AUTOSAR XML (schema 4-2-1)
package /ComponentTypes
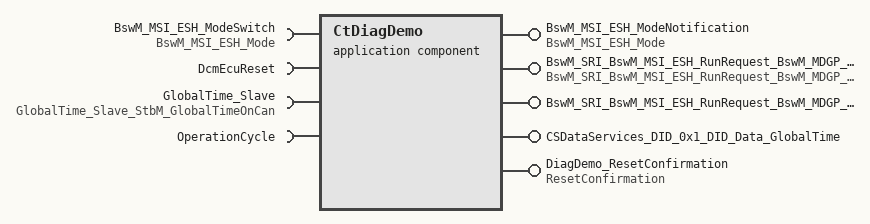
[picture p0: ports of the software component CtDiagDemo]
  application sw component type CtDiagDemo
    5 x provide port:
      BswM_MSI_ESH_ModeNotification: mode-switch-sender-com-spec{enhanced-mode-api=false, mode-group=BswM_MDGP_ESH_Mode, queue-length=1}, provided-interface=BswM_MSI_ESH_Mode
      BswM_SRI_BswM_MSI_ESH_RunRequest_BswM_MDGP_ESH_PostRunRequest: nonqueued-sender-com-spec{data-element=requestedMode, init-value=RELEASED}, provided-interface=BswM_SRI_BswM_MSI_ESH_RunRequest_BswM_MDGP_ESH_RunRequest
      BswM_SRI_BswM_MSI_ESH_RunRequest_BswM_MDGP_ESH_RunRequest: nonqueued-sender-com-spec{data-element=requestedMode, init-value=RELEASED}, provided-interface=BswM_SRI_BswM_MSI_ESH_RunRequest_BswM_MDGP_ESH_RunRequest
      CSDataServices_DID_0x1_DID_Data_GlobalTime: server-com-spec{operation=ReadData, queue-length=1}, provided-interface=CSDataServices_DID_0x1_DID_Data_GlobalTime
      DiagDemo_ResetConfirmation: server-com-spec{operation=ConfirmReset, queue-length=1}, provided-interface=ResetConfirmation
    4 x require port:
      BswM_MSI_ESH_ModeSwitch: mode-switch-receiver-com-spec{enhanced-mode-api=false, supports-asynchronous-mode-switch=false}, required-interface=BswM_MSI_ESH_Mode
      DcmEcuReset: mode-switch-receiver-com-spec{enhanced-mode-api=false, supports-asynchronous-mode-switch=false}, required-interface=DcmEcuReset
      GlobalTime_Slave: required-com-specs=[GetCurrentTime, GetRateDeviation, GetTimeLeap], required-interface=GlobalTime_Slave_StbM_GlobalTimeOnCan
      OperationCycle: required-com-specs=[GetOperationCycleState, SetOperationCycleState], required-interface=OperationCycle
    behavior CtDiagDemo_InternalBehavior: data-type-mapping=DemoTypeMapping
      operation invoked event OIT_CtDiagDemo_CSDataServices_Data_DID_0x1_DID_Data_GlobalTime_ReadData_CSDataServices_DID_0x1_DID_Data_GlobalTime_ReadData: start-on-event=CtDiagDemo_CSDataServices_Data_DID_0x1_DID_Data_GlobalTime_ReadData, operation=CSDataServices_DID_0x1_DID_Data_GlobalTime.ReadData
      init event CtDiagDemo_InitEvent: start-on-event=CtDiagDemo_Init
      swc mode switch event MST_CtDiagDemo_EcuReset_0: start-on-event=CtDiagDemo_RequestEcuReset, activation=ON-ENTRY, mode=DcmEcuReset.DcmEcuReset.EXECUTE
      operation invoked event OIT_DiagDemo_ResetConfirmation_ConfirmReset_DiagDemo_ResetConfirmation_ConfirmReset: start-on-event=DiagDemo_ResetConfirmation_ConfirmReset, operation=DiagDemo_ResetConfirmation.ConfirmReset
      per-instance-parameters:
        parameter data prototype calUseInObdVariant: sw-calibration-access=READ-WRITE, type=boolean, init-value=0
      4 x runnable:
        CtDiagDemo_CSDataServices_Data_DID_0x1_DID_Data_GlobalTime_ReadData
          sync call SC_GlobalTime_Slave_GetCurrentTime: operation=GlobalTime_Slave.GetCurrentTime, timeout=0
        CtDiagDemo_Init
          data-send-points:
            access SEND_BswM_SRI_BswM_MSI_ESH_RunRequest_BswM_MDGP_ESH_RunRequest_requestedMode: accessed-variable=BswM_SRI_BswM_MSI_ESH_RunRequest_BswM_MDGP_ESH_RunRequest.requestedMode
          sync call SC_OperationCycle_SetOperationCycleState: operation=OperationCycle.SetOperationCycleState, timeout=0
        CtDiagDemo_RequestEcuReset: mode-access-point=BswM_MSI_ESH_ModeSwitch.BswM_MDGP_ESH_Mode
          data-send-points:
            access SEND_BswM_SRI_BswM_MSI_ESH_RunRequest_BswM_MDGP_ESH_PostRunRequest_requestedMode: accessed-variable=BswM_SRI_BswM_MSI_ESH_RunRequest_BswM_MDGP_ESH_PostRunRequest.requestedMode
            access SEND_BswM_SRI_BswM_MSI_ESH_RunRequest_BswM_MDGP_ESH_RunRequest_requestedMode: accessed-variable=BswM_SRI_BswM_MSI_ESH_RunRequest_BswM_MDGP_ESH_RunRequest.requestedMode
          sync call SC_OperationCycle_SetOperationCycleState: operation=OperationCycle.SetOperationCycleState, timeout=0
        DiagDemo_ResetConfirmation_ConfirmReset: mode-access-point=BswM_MSI_ESH_ModeNotification.BswM_MDGP_ESH_Mode
          mode switch point SWITCH_BswM_MSI_ESH_ModeNotification_BswM_MDGP_ESH_Mode: mode-group=BswM_MSI_ESH_ModeNotification.BswM_MDGP_ESH_Mode
  swc implementation CtDiagDemo_Implementation: behavior=CtDiagDemo_InternalBehavior
    code-descriptors:
      code Default: artifact-descriptors=autosar-engineering-object={short-label=Default, category=SWSRC}
